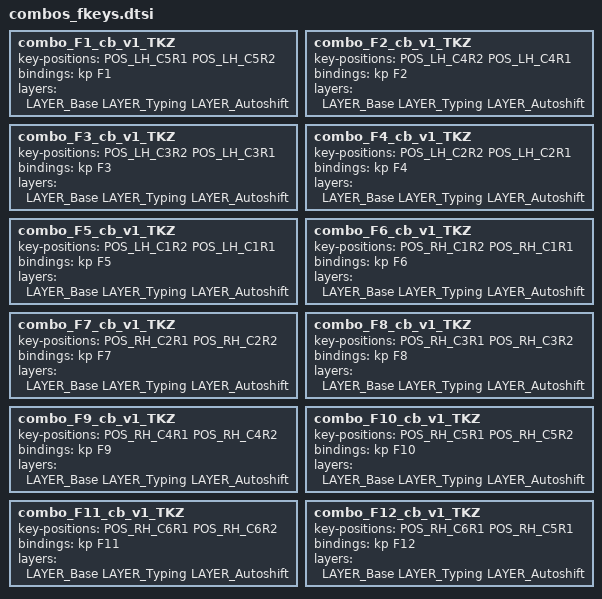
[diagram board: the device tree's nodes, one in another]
// F1 combo for Go60 - TailorKey
combo_F1_cb_v1_TKZ {
    key-positions = <POS_LH_C5R1 POS_LH_C5R2>;
    bindings = <&kp F1>;
    layers = <LAYER_Base LAYER_Typing LAYER_Autoshift>;
};

// F2 combo for Go60 - TailorKey
combo_F2_cb_v1_TKZ {
    key-positions = <POS_LH_C4R2 POS_LH_C4R1>;
    bindings = <&kp F2>;
    layers = <LAYER_Base LAYER_Typing LAYER_Autoshift>;
};

// F3 combo for Go60 - TailorKey
combo_F3_cb_v1_TKZ {
    key-positions = <POS_LH_C3R2 POS_LH_C3R1>;
    bindings = <&kp F3>;
    layers = <LAYER_Base LAYER_Typing LAYER_Autoshift>;
};

// F4 combo for Go60 - TailorKey
combo_F4_cb_v1_TKZ {
    key-positions = <POS_LH_C2R2 POS_LH_C2R1>;
    bindings = <&kp F4>;
    layers = <LAYER_Base LAYER_Typing LAYER_Autoshift>;
};

// F5 combo for Go60 - TailorKey
combo_F5_cb_v1_TKZ {
    key-positions = <POS_LH_C1R2 POS_LH_C1R1>;
    bindings = <&kp F5>;
    layers = <LAYER_Base LAYER_Typing LAYER_Autoshift>;
};

// F6 combo for Go60 - TailorKey
combo_F6_cb_v1_TKZ {
    key-positions = <POS_RH_C1R2 POS_RH_C1R1>;
    bindings = <&kp F6>;
    layers = <LAYER_Base LAYER_Typing LAYER_Autoshift>;
};

// F7 combo for Go60 - TailorKey
combo_F7_cb_v1_TKZ {
    key-positions = <POS_RH_C2R1 POS_RH_C2R2>;
    bindings = <&kp F7>;
    layers = <LAYER_Base LAYER_Typing LAYER_Autoshift>;
};

// F8 combo for Go60 - TailorKey
combo_F8_cb_v1_TKZ {
    key-positions = <POS_RH_C3R1 POS_RH_C3R2>;
    bindings = <&kp F8>;
    layers = <LAYER_Base LAYER_Typing LAYER_Autoshift>;
};

// F9 combo for Go60 - TailorKey
combo_F9_cb_v1_TKZ {
    key-positions = <POS_RH_C4R1 POS_RH_C4R2>;
    bindings = <&kp F9>;
    layers = <LAYER_Base LAYER_Typing LAYER_Autoshift>;
};

// F10 combo for Go60 - TailorKey
combo_F10_cb_v1_TKZ {
    key-positions = <POS_RH_C5R1 POS_RH_C5R2>;
    bindings = <&kp F10>;
    layers = <LAYER_Base LAYER_Typing LAYER_Autoshift>;
};

// F11 combo for Go60 - TailorKey
combo_F11_cb_v1_TKZ {
    key-positions = <POS_RH_C6R1 POS_RH_C6R2>;
    bindings = <&kp F11>;
    layers = <LAYER_Base LAYER_Typing LAYER_Autoshift>;
};

// F12 combo for Go60 - TailorKey
combo_F12_cb_v1_TKZ {
    key-positions = <POS_RH_C6R1 POS_RH_C5R1>;
    bindings = <&kp F12>;
    layers = <LAYER_Base LAYER_Typing LAYER_Autoshift>;
};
